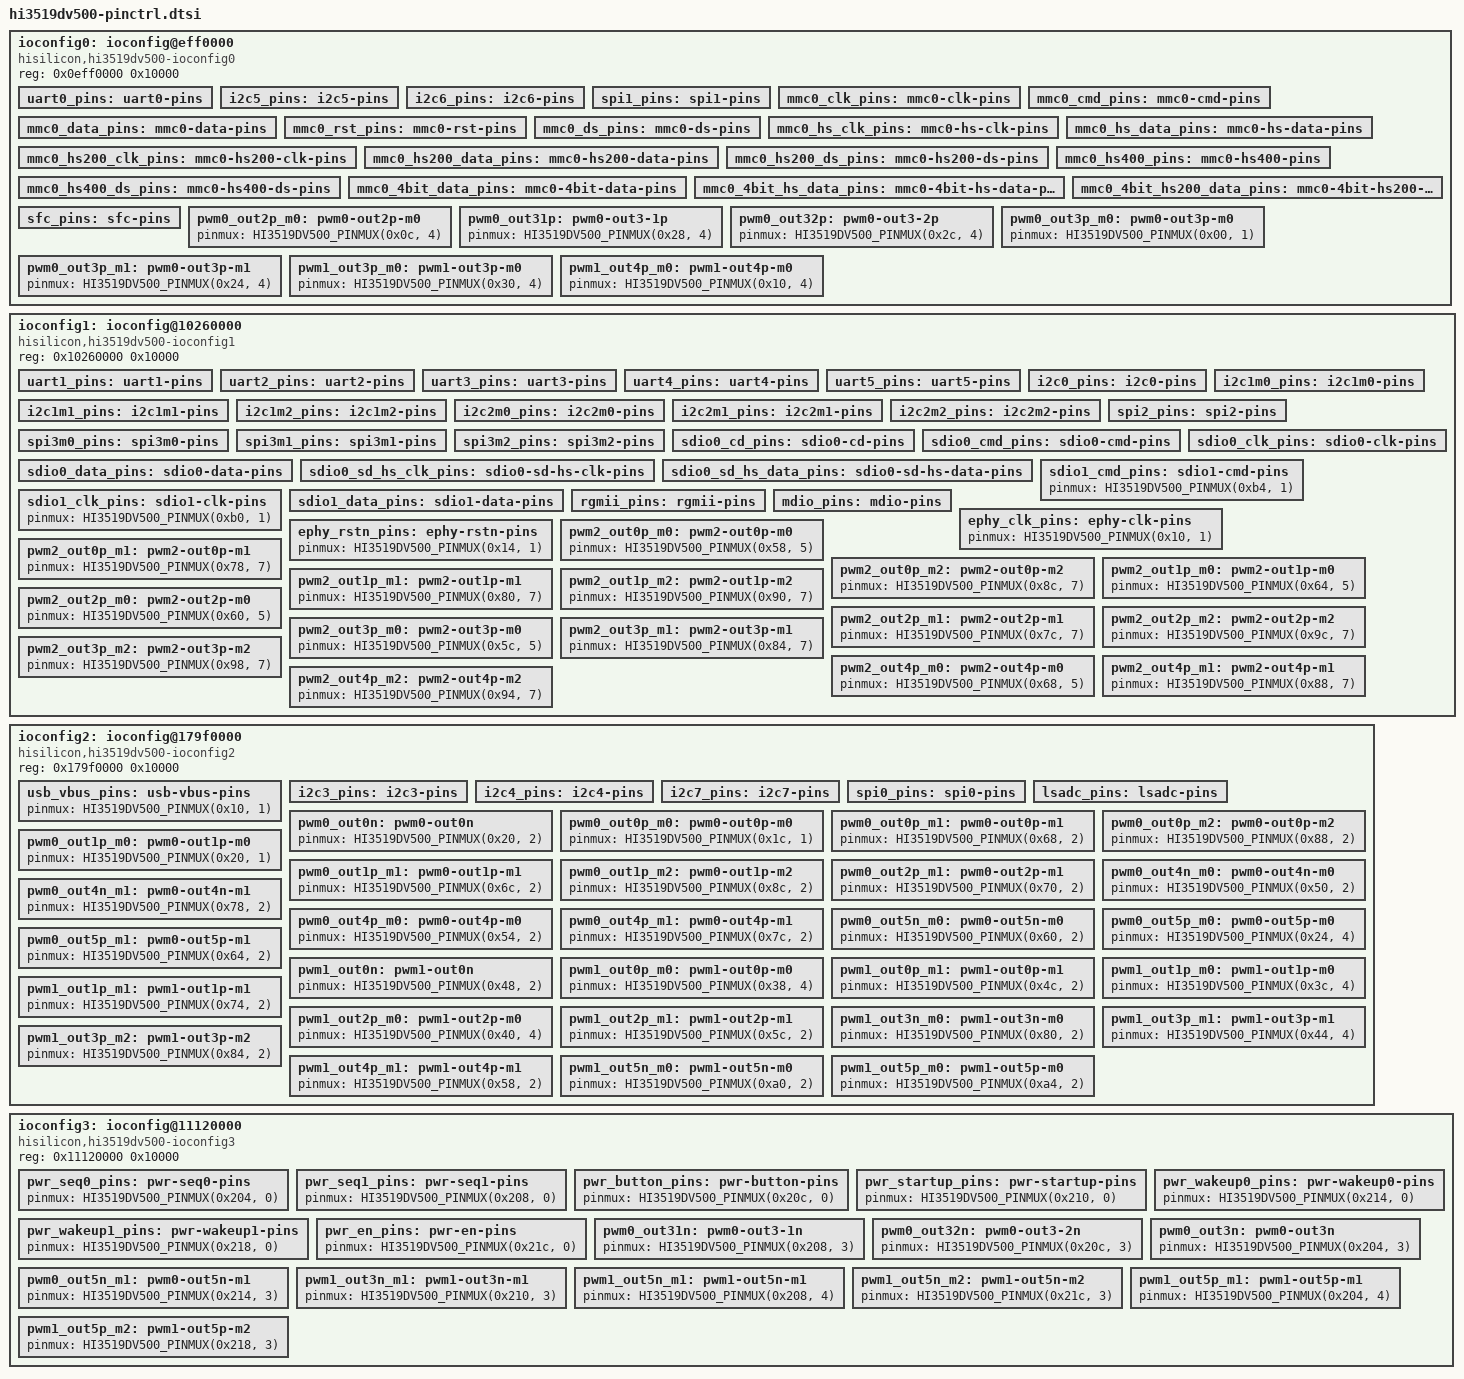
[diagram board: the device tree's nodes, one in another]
// SPDX-License-Identifier: GPL-2.0-only OR BSD-2-Clause
/*
 * Pin controller groups for the HiSilicon Hi3519DV500 SoC.
 *
 * The four ioconfig windows are included from the soc node of
 * hi3519dv500.dtsi; boards reference the groups by phandle and
 * override the electrical settings they need.
 */

ioconfig0: ioconfig@eff0000 {
	compatible = "hisilicon,hi3519dv500-ioconfig0";
	reg = <0x0eff0000 0x10000>;

	/* Neutral mux-only defaults; boards tune the electrical
	 * configuration through their own groups.  Signal order:
	 * RXD,TXD / SDA,SCL / SCLK,SDI,SDO,CSN.
	 */
	uart0_pins: uart0-pins {
		pinmux = <HI3519DV500_PINMUX(0x54, 1)>,
			 <HI3519DV500_PINMUX(0x58, 1)>;
	};

	i2c5_pins: i2c5-pins {
		pinmux = <HI3519DV500_PINMUX(0x28, 2)>,
			 <HI3519DV500_PINMUX(0x24, 2)>;
	};

	i2c6_pins: i2c6-pins {
		pinmux = <HI3519DV500_PINMUX(0x30, 2)>,
			 <HI3519DV500_PINMUX(0x2c, 2)>;
	};

	spi1_pins: spi1-pins {
		pinmux = <HI3519DV500_PINMUX(0x24, 1)>,
			 <HI3519DV500_PINMUX(0x2c, 1)>,
			 <HI3519DV500_PINMUX(0x28, 1)>,
			 <HI3519DV500_PINMUX(0x30, 1)>;
	};

	/* The eMMC pads keep their power-on pull mode: CLK and
	 * DS pull-down, CMD, DATA and RST pull-up.
	 */
	mmc0_clk_pins: mmc0-clk-pins {
		pinmux = <HI3519DV500_PINMUX(0x34, 1)>;
		bias-pull-down;
		drive-strength = <3>;
	};

	mmc0_cmd_pins: mmc0-cmd-pins {
		pinmux = <HI3519DV500_PINMUX(0x38, 1)>;
		bias-pull-up;
		drive-strength = <2>;
	};

	/* D0..D3 use function 1, D4..D7 function 3 */
	mmc0_data_pins: mmc0-data-pins {
		pinmux = <HI3519DV500_PINMUX(0x3c, 1)>,
			 <HI3519DV500_PINMUX(0x40, 1)>,
			 <HI3519DV500_PINMUX(0x44, 1)>,
			 <HI3519DV500_PINMUX(0x48, 1)>,
			 <HI3519DV500_PINMUX(0x24, 3)>,
			 <HI3519DV500_PINMUX(0x28, 3)>,
			 <HI3519DV500_PINMUX(0x2c, 3)>,
			 <HI3519DV500_PINMUX(0x30, 3)>;
		bias-pull-up;
		drive-strength = <2>;
	};

	mmc0_rst_pins: mmc0-rst-pins {
		pinmux = <HI3519DV500_PINMUX(0x4c, 1)>;
		bias-pull-up;
		drive-strength = <0>;
	};

	mmc0_ds_pins: mmc0-ds-pins {
		pinmux = <HI3519DV500_PINMUX(0x50, 1)>;
		bias-pull-down;
		drive-strength = <0>;
	};

	/* The speed states only override the drive strength,
	 * matching the vendor tuning: CMD shares the DATA level
	 * in HS/HS200 while all lines share one level in HS400.
	 */
	mmc0_hs_clk_pins: mmc0-hs-clk-pins {
		pinmux = <HI3519DV500_PINMUX(0x34, 1)>;
		drive-strength = <4>;
	};

	/* CMD and D0..D7 share one level in HS */
	mmc0_hs_data_pins: mmc0-hs-data-pins {
		pinmux = <HI3519DV500_PINMUX(0x38, 1)>,
			 <HI3519DV500_PINMUX(0x3c, 1)>,
			 <HI3519DV500_PINMUX(0x40, 1)>,
			 <HI3519DV500_PINMUX(0x44, 1)>,
			 <HI3519DV500_PINMUX(0x48, 1)>,
			 <HI3519DV500_PINMUX(0x24, 3)>,
			 <HI3519DV500_PINMUX(0x28, 3)>,
			 <HI3519DV500_PINMUX(0x2c, 3)>,
			 <HI3519DV500_PINMUX(0x30, 3)>;
		drive-strength = <3>;
	};

	mmc0_hs200_clk_pins: mmc0-hs200-clk-pins {
		pinmux = <HI3519DV500_PINMUX(0x34, 1)>;
		drive-strength = <15>;
	};

	/* CMD and D0..D7 share one level in HS200 */
	mmc0_hs200_data_pins: mmc0-hs200-data-pins {
		pinmux = <HI3519DV500_PINMUX(0x38, 1)>,
			 <HI3519DV500_PINMUX(0x3c, 1)>,
			 <HI3519DV500_PINMUX(0x40, 1)>,
			 <HI3519DV500_PINMUX(0x44, 1)>,
			 <HI3519DV500_PINMUX(0x48, 1)>,
			 <HI3519DV500_PINMUX(0x24, 3)>,
			 <HI3519DV500_PINMUX(0x28, 3)>,
			 <HI3519DV500_PINMUX(0x2c, 3)>,
			 <HI3519DV500_PINMUX(0x30, 3)>;
		drive-strength = <12>;
	};

	mmc0_hs200_ds_pins: mmc0-hs200-ds-pins {
		pinmux = <HI3519DV500_PINMUX(0x50, 1)>;
		drive-strength = <0>;
	};

	/* All lines share one level in HS400 */
	mmc0_hs400_pins: mmc0-hs400-pins {
		pinmux = <HI3519DV500_PINMUX(0x34, 1)>,
			 <HI3519DV500_PINMUX(0x38, 1)>,
			 <HI3519DV500_PINMUX(0x3c, 1)>,
			 <HI3519DV500_PINMUX(0x40, 1)>,
			 <HI3519DV500_PINMUX(0x44, 1)>,
			 <HI3519DV500_PINMUX(0x48, 1)>,
			 <HI3519DV500_PINMUX(0x24, 3)>,
			 <HI3519DV500_PINMUX(0x28, 3)>,
			 <HI3519DV500_PINMUX(0x2c, 3)>,
			 <HI3519DV500_PINMUX(0x30, 3)>;
		drive-strength = <15>;
	};

	mmc0_hs400_ds_pins: mmc0-hs400-ds-pins {
		pinmux = <HI3519DV500_PINMUX(0x50, 1)>;
		drive-strength = <0>;
	};

	/*
	 * Variants for boards that wire only D0..D3.  The pads
	 * that D4..D7 would take (0x24, 0x28, 0x2c and 0x30)
	 * stay free for the SPI1 and I2C controllers.
	 */
	mmc0_4bit_data_pins: mmc0-4bit-data-pins {
		pinmux = <HI3519DV500_PINMUX(0x3c, 1)>,
			 <HI3519DV500_PINMUX(0x40, 1)>,
			 <HI3519DV500_PINMUX(0x44, 1)>,
			 <HI3519DV500_PINMUX(0x48, 1)>;
		bias-pull-up;
		drive-strength = <2>;
	};

	mmc0_4bit_hs_data_pins: mmc0-4bit-hs-data-pins {
		pinmux = <HI3519DV500_PINMUX(0x38, 1)>,
			 <HI3519DV500_PINMUX(0x3c, 1)>,
			 <HI3519DV500_PINMUX(0x40, 1)>,
			 <HI3519DV500_PINMUX(0x44, 1)>,
			 <HI3519DV500_PINMUX(0x48, 1)>;
		drive-strength = <3>;
	};

	mmc0_4bit_hs200_data_pins: mmc0-4bit-hs200-data-pins {
		pinmux = <HI3519DV500_PINMUX(0x38, 1)>,
			 <HI3519DV500_PINMUX(0x3c, 1)>,
			 <HI3519DV500_PINMUX(0x40, 1)>,
			 <HI3519DV500_PINMUX(0x44, 1)>,
			 <HI3519DV500_PINMUX(0x48, 1)>;
		drive-strength = <12>;
	};

	sfc_pins: sfc-pins {
		pinmux = <HI3519DV500_PINMUX(0x34, 0)>,
			 <HI3519DV500_PINMUX(0x38, 0)>,
			 <HI3519DV500_PINMUX(0x3c, 0)>,
			 <HI3519DV500_PINMUX(0x40, 0)>,
			 <HI3519DV500_PINMUX(0x44, 0)>,
			 <HI3519DV500_PINMUX(0x48, 0)>;
	};

	pwm0_out2p_m0: pwm0-out2p-m0 {
		pinmux = <HI3519DV500_PINMUX(0x0c, 4)>;
	};
	pwm0_out31p: pwm0-out3-1p {
		pinmux = <HI3519DV500_PINMUX(0x28, 4)>;
	};
	pwm0_out32p: pwm0-out3-2p {
		pinmux = <HI3519DV500_PINMUX(0x2c, 4)>;
	};
	pwm0_out3p_m0: pwm0-out3p-m0 {
		pinmux = <HI3519DV500_PINMUX(0x00, 1)>;
	};
	pwm0_out3p_m1: pwm0-out3p-m1 {
		pinmux = <HI3519DV500_PINMUX(0x24, 4)>;
	};
	pwm1_out3p_m0: pwm1-out3p-m0 {
		pinmux = <HI3519DV500_PINMUX(0x30, 4)>;
	};
	pwm1_out4p_m0: pwm1-out4p-m0 {
		pinmux = <HI3519DV500_PINMUX(0x10, 4)>;
	};
};

ioconfig1: ioconfig@10260000 {
	compatible = "hisilicon,hi3519dv500-ioconfig1";
	reg = <0x10260000 0x10000>;

	uart1_pins: uart1-pins {
		pinmux = <HI3519DV500_PINMUX(0xd8, 1)>,
			 <HI3519DV500_PINMUX(0xdc, 1)>;
		bias-pull-up;
	};

	uart2_pins: uart2-pins {
		pinmux = <HI3519DV500_PINMUX(0x00, 1)>,
			 <HI3519DV500_PINMUX(0x04, 1)>;
	};

	uart3_pins: uart3-pins {
		pinmux = <HI3519DV500_PINMUX(0xe4, 2)>,
			 <HI3519DV500_PINMUX(0xe0, 2)>;
	};

	uart4_pins: uart4-pins {
		pinmux = <HI3519DV500_PINMUX(0x08, 2)>,
			 <HI3519DV500_PINMUX(0x0c, 2)>;
		bias-pull-up;
	};

	uart5_pins: uart5-pins {
		pinmux = <HI3519DV500_PINMUX(0x80, 6)>,
			 <HI3519DV500_PINMUX(0x84, 6)>;
	};

	i2c0_pins: i2c0-pins {
		pinmux = <HI3519DV500_PINMUX(0x6c, 1)>,
			 <HI3519DV500_PINMUX(0x70, 1)>;
	};

	/* i2c1, i2c2 and spi3 have three pad options each,
	 * named m0..m2 in ascending register offset order
	 */
	i2c1m0_pins: i2c1m0-pins {
		pinmux = <HI3519DV500_PINMUX(0x00, 5)>,
			 <HI3519DV500_PINMUX(0x04, 5)>;
	};

	i2c1m1_pins: i2c1m1-pins {
		pinmux = <HI3519DV500_PINMUX(0x30, 2)>,
			 <HI3519DV500_PINMUX(0x34, 2)>;
	};

	i2c1m2_pins: i2c1m2-pins {
		pinmux = <HI3519DV500_PINMUX(0x94, 3)>,
			 <HI3519DV500_PINMUX(0x90, 3)>;
	};

	i2c2m0_pins: i2c2m0-pins {
		pinmux = <HI3519DV500_PINMUX(0x08, 5)>,
			 <HI3519DV500_PINMUX(0x0c, 5)>;
	};

	i2c2m1_pins: i2c2m1-pins {
		pinmux = <HI3519DV500_PINMUX(0x14, 2)>,
			 <HI3519DV500_PINMUX(0x20, 2)>;
	};

	i2c2m2_pins: i2c2m2-pins {
		pinmux = <HI3519DV500_PINMUX(0x80, 3)>,
			 <HI3519DV500_PINMUX(0x84, 3)>;
	};

	spi2_pins: spi2-pins {
		pinmux = <HI3519DV500_PINMUX(0x04, 3)>,
			 <HI3519DV500_PINMUX(0x08, 3)>,
			 <HI3519DV500_PINMUX(0x0c, 3)>,
			 <HI3519DV500_PINMUX(0x00, 3)>;
	};

	spi3m0_pins: spi3m0-pins {
		pinmux = <HI3519DV500_PINMUX(0x3c, 2)>,
			 <HI3519DV500_PINMUX(0x2c, 2)>,
			 <HI3519DV500_PINMUX(0x28, 2)>,
			 <HI3519DV500_PINMUX(0x40, 2)>,
			 <HI3519DV500_PINMUX(0x44, 2)>;
	};

	spi3m1_pins: spi3m1-pins {
		pinmux = <HI3519DV500_PINMUX(0x5c, 3)>,
			 <HI3519DV500_PINMUX(0x60, 3)>,
			 <HI3519DV500_PINMUX(0x64, 3)>,
			 <HI3519DV500_PINMUX(0x58, 3)>,
			 <HI3519DV500_PINMUX(0x68, 3)>;
	};

	spi3m2_pins: spi3m2-pins {
		pinmux = <HI3519DV500_PINMUX(0x88, 3)>,
			 <HI3519DV500_PINMUX(0x7c, 3)>,
			 <HI3519DV500_PINMUX(0x98, 3)>,
			 <HI3519DV500_PINMUX(0x78, 3)>,
			 <HI3519DV500_PINMUX(0x9c, 3)>;
	};

	sdio0_cd_pins: sdio0-cd-pins {
		pinmux = <HI3519DV500_PINMUX(0xd0, 1)>;
		bias-pull-up;
	};

	sdio0_cmd_pins: sdio0-cmd-pins {
		pinmux = <HI3519DV500_PINMUX(0xb8, 1)>;
		bias-pull-up;
		drive-strength = <2>;
	};

	sdio0_clk_pins: sdio0-clk-pins {
		pinmux = <HI3519DV500_PINMUX(0xcc, 1)>;
		bias-pull-down;
		drive-strength = <3>;
	};

	sdio0_data_pins: sdio0-data-pins {
		pinmux = <HI3519DV500_PINMUX(0xbc, 1)>,
			 <HI3519DV500_PINMUX(0xc0, 1)>,
			 <HI3519DV500_PINMUX(0xc4, 1)>,
			 <HI3519DV500_PINMUX(0xc8, 1)>;
		bias-pull-up;
		drive-strength = <2>;
	};

	/* SD_HS raises the drive strength on every line */
	sdio0_sd_hs_clk_pins: sdio0-sd-hs-clk-pins {
		pinmux = <HI3519DV500_PINMUX(0xcc, 1)>;
		bias-pull-down;
		drive-strength = <4>;
	};

	sdio0_sd_hs_data_pins: sdio0-sd-hs-data-pins {
		pinmux = <HI3519DV500_PINMUX(0xb8, 1)>,
			 <HI3519DV500_PINMUX(0xbc, 1)>,
			 <HI3519DV500_PINMUX(0xc0, 1)>,
			 <HI3519DV500_PINMUX(0xc4, 1)>,
			 <HI3519DV500_PINMUX(0xc8, 1)>;
		drive-strength = <3>;
	};

	sdio1_cmd_pins: sdio1-cmd-pins {
		pinmux = <HI3519DV500_PINMUX(0xb4, 1)>;
	};

	sdio1_clk_pins: sdio1-clk-pins {
		pinmux = <HI3519DV500_PINMUX(0xb0, 1)>;
	};

	sdio1_data_pins: sdio1-data-pins {
		pinmux = <HI3519DV500_PINMUX(0xa0, 1)>,
			 <HI3519DV500_PINMUX(0xa4, 1)>,
			 <HI3519DV500_PINMUX(0xa8, 1)>,
			 <HI3519DV500_PINMUX(0xac, 1)>;
	};

	rgmii_pins: rgmii-pins {
		pinmux = <HI3519DV500_PINMUX(0x28, 1)>,
			 <HI3519DV500_PINMUX(0x2c, 1)>,
			 <HI3519DV500_PINMUX(0x30, 1)>,
			 <HI3519DV500_PINMUX(0x34, 1)>,
			 <HI3519DV500_PINMUX(0x38, 1)>,
			 <HI3519DV500_PINMUX(0x3c, 1)>,
			 <HI3519DV500_PINMUX(0x40, 1)>,
			 <HI3519DV500_PINMUX(0x44, 1)>,
			 <HI3519DV500_PINMUX(0x48, 1)>,
			 <HI3519DV500_PINMUX(0x4c, 1)>,
			 <HI3519DV500_PINMUX(0x50, 1)>,
			 <HI3519DV500_PINMUX(0x54, 1)>;
	};

	mdio_pins: mdio-pins {
		pinmux = <HI3519DV500_PINMUX(0x1c, 1)>,
			 <HI3519DV500_PINMUX(0x20, 1)>;
	};

	ephy_clk_pins: ephy-clk-pins {
		pinmux = <HI3519DV500_PINMUX(0x10, 1)>;
	};

	ephy_rstn_pins: ephy-rstn-pins {
		pinmux = <HI3519DV500_PINMUX(0x14, 1)>;
	};

	pwm2_out0p_m0: pwm2-out0p-m0 {
		pinmux = <HI3519DV500_PINMUX(0x58, 5)>;
	};
	pwm2_out0p_m1: pwm2-out0p-m1 {
		pinmux = <HI3519DV500_PINMUX(0x78, 7)>;
	};
	pwm2_out0p_m2: pwm2-out0p-m2 {
		pinmux = <HI3519DV500_PINMUX(0x8c, 7)>;
	};
	pwm2_out1p_m0: pwm2-out1p-m0 {
		pinmux = <HI3519DV500_PINMUX(0x64, 5)>;
	};
	pwm2_out1p_m1: pwm2-out1p-m1 {
		pinmux = <HI3519DV500_PINMUX(0x80, 7)>;
	};
	pwm2_out1p_m2: pwm2-out1p-m2 {
		pinmux = <HI3519DV500_PINMUX(0x90, 7)>;
	};
	pwm2_out2p_m0: pwm2-out2p-m0 {
		pinmux = <HI3519DV500_PINMUX(0x60, 5)>;
	};
	pwm2_out2p_m1: pwm2-out2p-m1 {
		pinmux = <HI3519DV500_PINMUX(0x7c, 7)>;
	};
	pwm2_out2p_m2: pwm2-out2p-m2 {
		pinmux = <HI3519DV500_PINMUX(0x9c, 7)>;
	};
	pwm2_out3p_m0: pwm2-out3p-m0 {
		pinmux = <HI3519DV500_PINMUX(0x5c, 5)>;
	};
	pwm2_out3p_m1: pwm2-out3p-m1 {
		pinmux = <HI3519DV500_PINMUX(0x84, 7)>;
	};
	pwm2_out3p_m2: pwm2-out3p-m2 {
		pinmux = <HI3519DV500_PINMUX(0x98, 7)>;
	};
	pwm2_out4p_m0: pwm2-out4p-m0 {
		pinmux = <HI3519DV500_PINMUX(0x68, 5)>;
	};
	pwm2_out4p_m1: pwm2-out4p-m1 {
		pinmux = <HI3519DV500_PINMUX(0x88, 7)>;
	};
	pwm2_out4p_m2: pwm2-out4p-m2 {
		pinmux = <HI3519DV500_PINMUX(0x94, 7)>;
	};
};

ioconfig2: ioconfig@179f0000 {
	compatible = "hisilicon,hi3519dv500-ioconfig2";
	reg = <0x179f0000 0x10000>;

	usb_vbus_pins: usb-vbus-pins {
		pinmux = <HI3519DV500_PINMUX(0x10, 1)>;
	};

	i2c3_pins: i2c3-pins {
		pinmux = <HI3519DV500_PINMUX(0x28, 2)>,
			 <HI3519DV500_PINMUX(0x2c, 2)>;
	};

	i2c4_pins: i2c4-pins {
		pinmux = <HI3519DV500_PINMUX(0x30, 2)>,
			 <HI3519DV500_PINMUX(0x34, 2)>;
	};

	i2c7_pins: i2c7-pins {
		pinmux = <HI3519DV500_PINMUX(0x00, 2)>,
			 <HI3519DV500_PINMUX(0x04, 2)>;
	};

	spi0_pins: spi0-pins {
		pinmux = <HI3519DV500_PINMUX(0x34, 1)>,
			 <HI3519DV500_PINMUX(0x2c, 1)>,
			 <HI3519DV500_PINMUX(0x30, 1)>,
			 <HI3519DV500_PINMUX(0x28, 1)>,
			 <HI3519DV500_PINMUX(0x24, 1)>;
	};

	lsadc_pins: lsadc-pins {
		pinmux = <HI3519DV500_PINMUX(0x00, 0)>,
			 <HI3519DV500_PINMUX(0x04, 0)>,
			 <HI3519DV500_PINMUX(0x08, 0)>,
			 <HI3519DV500_PINMUX(0x0c, 0)>;
	};

	pwm0_out0n: pwm0-out0n {
		pinmux = <HI3519DV500_PINMUX(0x20, 2)>;
	};
	pwm0_out0p_m0: pwm0-out0p-m0 {
		pinmux = <HI3519DV500_PINMUX(0x1c, 1)>;
	};
	pwm0_out0p_m1: pwm0-out0p-m1 {
		pinmux = <HI3519DV500_PINMUX(0x68, 2)>;
	};
	pwm0_out0p_m2: pwm0-out0p-m2 {
		pinmux = <HI3519DV500_PINMUX(0x88, 2)>;
	};
	pwm0_out1p_m0: pwm0-out1p-m0 {
		pinmux = <HI3519DV500_PINMUX(0x20, 1)>;
	};
	pwm0_out1p_m1: pwm0-out1p-m1 {
		pinmux = <HI3519DV500_PINMUX(0x6c, 2)>;
	};
	pwm0_out1p_m2: pwm0-out1p-m2 {
		pinmux = <HI3519DV500_PINMUX(0x8c, 2)>;
	};
	pwm0_out2p_m1: pwm0-out2p-m1 {
		pinmux = <HI3519DV500_PINMUX(0x70, 2)>;
	};
	pwm0_out4n_m0: pwm0-out4n-m0 {
		pinmux = <HI3519DV500_PINMUX(0x50, 2)>;
	};
	pwm0_out4n_m1: pwm0-out4n-m1 {
		pinmux = <HI3519DV500_PINMUX(0x78, 2)>;
	};
	pwm0_out4p_m0: pwm0-out4p-m0 {
		pinmux = <HI3519DV500_PINMUX(0x54, 2)>;
	};
	pwm0_out4p_m1: pwm0-out4p-m1 {
		pinmux = <HI3519DV500_PINMUX(0x7c, 2)>;
	};
	pwm0_out5n_m0: pwm0-out5n-m0 {
		pinmux = <HI3519DV500_PINMUX(0x60, 2)>;
	};
	pwm0_out5p_m0: pwm0-out5p-m0 {
		pinmux = <HI3519DV500_PINMUX(0x24, 4)>;
	};
	pwm0_out5p_m1: pwm0-out5p-m1 {
		pinmux = <HI3519DV500_PINMUX(0x64, 2)>;
	};
	pwm1_out0n: pwm1-out0n {
		pinmux = <HI3519DV500_PINMUX(0x48, 2)>;
	};
	pwm1_out0p_m0: pwm1-out0p-m0 {
		pinmux = <HI3519DV500_PINMUX(0x38, 4)>;
	};
	pwm1_out0p_m1: pwm1-out0p-m1 {
		pinmux = <HI3519DV500_PINMUX(0x4c, 2)>;
	};
	pwm1_out1p_m0: pwm1-out1p-m0 {
		pinmux = <HI3519DV500_PINMUX(0x3c, 4)>;
	};
	pwm1_out1p_m1: pwm1-out1p-m1 {
		pinmux = <HI3519DV500_PINMUX(0x74, 2)>;
	};
	pwm1_out2p_m0: pwm1-out2p-m0 {
		pinmux = <HI3519DV500_PINMUX(0x40, 4)>;
	};
	pwm1_out2p_m1: pwm1-out2p-m1 {
		pinmux = <HI3519DV500_PINMUX(0x5c, 2)>;
	};
	pwm1_out3n_m0: pwm1-out3n-m0 {
		pinmux = <HI3519DV500_PINMUX(0x80, 2)>;
	};
	pwm1_out3p_m1: pwm1-out3p-m1 {
		pinmux = <HI3519DV500_PINMUX(0x44, 4)>;
	};
	pwm1_out3p_m2: pwm1-out3p-m2 {
		pinmux = <HI3519DV500_PINMUX(0x84, 2)>;
	};
	pwm1_out4p_m1: pwm1-out4p-m1 {
		pinmux = <HI3519DV500_PINMUX(0x58, 2)>;
	};
	pwm1_out5n_m0: pwm1-out5n-m0 {
		pinmux = <HI3519DV500_PINMUX(0xa0, 2)>;
	};
	pwm1_out5p_m0: pwm1-out5p-m0 {
		pinmux = <HI3519DV500_PINMUX(0xa4, 2)>;
	};
};

ioconfig3: ioconfig@11120000 {
	compatible = "hisilicon,hi3519dv500-ioconfig3";
	reg = <0x11120000 0x10000>;

	/* The power management pads sit at 0x200 in this block. */
	pwr_seq0_pins: pwr-seq0-pins {
		pinmux = <HI3519DV500_PINMUX(0x204, 0)>;
	};

	pwr_seq1_pins: pwr-seq1-pins {
		pinmux = <HI3519DV500_PINMUX(0x208, 0)>;
	};

	pwr_button_pins: pwr-button-pins {
		pinmux = <HI3519DV500_PINMUX(0x20c, 0)>;
	};

	pwr_startup_pins: pwr-startup-pins {
		pinmux = <HI3519DV500_PINMUX(0x210, 0)>;
	};

	pwr_wakeup0_pins: pwr-wakeup0-pins {
		pinmux = <HI3519DV500_PINMUX(0x214, 0)>;
	};

	pwr_wakeup1_pins: pwr-wakeup1-pins {
		pinmux = <HI3519DV500_PINMUX(0x218, 0)>;
	};

	pwr_en_pins: pwr-en-pins {
		pinmux = <HI3519DV500_PINMUX(0x21c, 0)>;
	};

	pwm0_out31n: pwm0-out3-1n {
		pinmux = <HI3519DV500_PINMUX(0x208, 3)>;
	};
	pwm0_out32n: pwm0-out3-2n {
		pinmux = <HI3519DV500_PINMUX(0x20c, 3)>;
	};
	pwm0_out3n: pwm0-out3n {
		pinmux = <HI3519DV500_PINMUX(0x204, 3)>;
	};
	pwm0_out5n_m1: pwm0-out5n-m1 {
		pinmux = <HI3519DV500_PINMUX(0x214, 3)>;
	};
	pwm1_out3n_m1: pwm1-out3n-m1 {
		pinmux = <HI3519DV500_PINMUX(0x210, 3)>;
	};
	pwm1_out5n_m1: pwm1-out5n-m1 {
		pinmux = <HI3519DV500_PINMUX(0x208, 4)>;
	};
	pwm1_out5n_m2: pwm1-out5n-m2 {
		pinmux = <HI3519DV500_PINMUX(0x21c, 3)>;
	};
	pwm1_out5p_m1: pwm1-out5p-m1 {
		pinmux = <HI3519DV500_PINMUX(0x204, 4)>;
	};
	pwm1_out5p_m2: pwm1-out5p-m2 {
		pinmux = <HI3519DV500_PINMUX(0x218, 3)>;
	};
};
